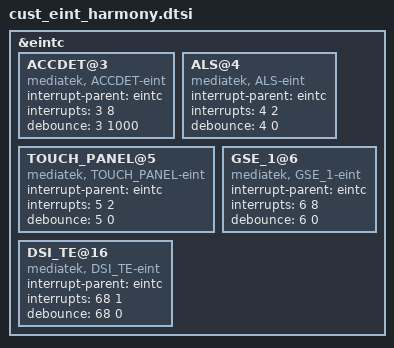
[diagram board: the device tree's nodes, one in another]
/*
 * Generated by MTK SP Drv_CodeGen Version 03.13.6  for MT6580. Copyright MediaTek Inc. (C) 2013.
 * Wed May 10 15:14:16 2017
 * Do Not Modify the File.
 */

/*************************
 * EINT DTSI File
*************************/

&eintc {
	ACCDET@3 {
		compatible = "mediatek, ACCDET-eint";
		interrupt-parent = <&eintc>;
		interrupts = <3 8>;
		debounce = <3 1000>;
	};

	ALS@4 {
		compatible = "mediatek, ALS-eint";
		interrupt-parent = <&eintc>;
		interrupts = <4 2>;
		debounce = <4 0>;
	};

	TOUCH_PANEL@5 {
		compatible = "mediatek, TOUCH_PANEL-eint";
		interrupt-parent = <&eintc>;
		interrupts = <5 2>;
		debounce = <5 0>;
	};

	GSE_1@6 {
		compatible = "mediatek, GSE_1-eint";
		interrupt-parent = <&eintc>;
		interrupts = <6 8>;
		debounce = <6 0>;
	};

	DSI_TE@16 {
		compatible = "mediatek, DSI_TE-eint";
		interrupt-parent = <&eintc>;
		interrupts = <68 1>;
		debounce = <68 0>;
	};

};
